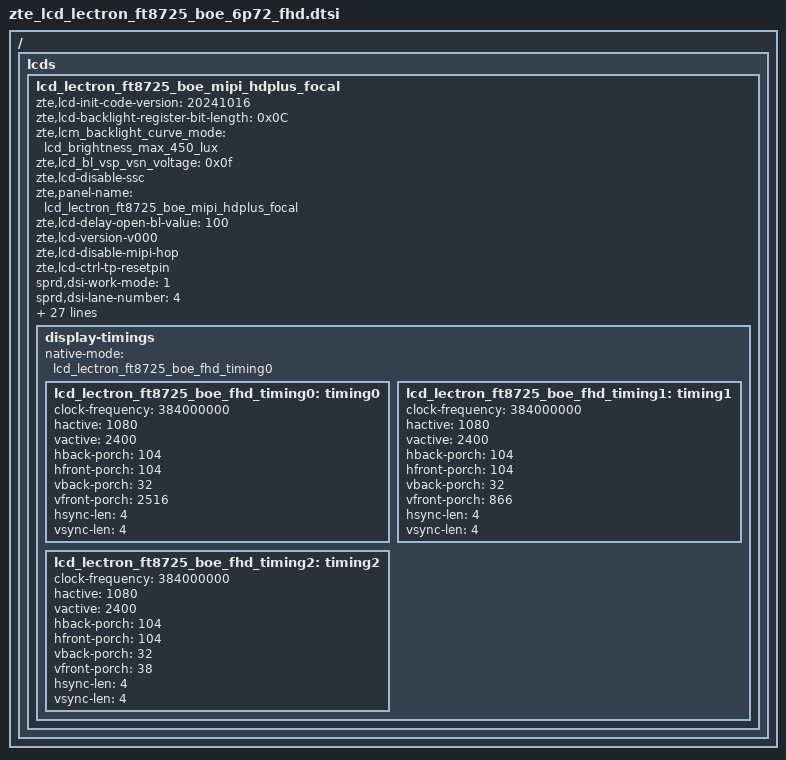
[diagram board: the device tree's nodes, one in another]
/ {
	fragment {
		target-path = "/";
		__overlay__ {
			lcds {
				lcd_lectron_ft8725_boe_mipi_hdplus_focal: lcd_lectron_ft8725_boe_mipi_hdplus_focal {
					zte,lcd-init-code-version = "20241016";

					zte,lcd-backlight-register-bit-length = <0x0C>;
					zte,lcm_backlight_curve_mode = "lcd_brightness_max_450_lux";
					zte,lcd_bl_vsp_vsn_voltage = <0x0f>;
					zte,lcd-disable-ssc;
					zte,panel-name = "lcd_lectron_ft8725_boe_mipi_hdplus_focal";
					zte,lcd-delay-open-bl-value = <100>;
					zte,lcd-version-v000;
					zte,lcd-disable-mipi-hop;
					zte,lcd-ctrl-tp-resetpin;

					sprd,dsi-work-mode = <1>;
					sprd,dsi-lane-number = <4>;
					sprd,dsi-color-format = "dsc";
					sprd,phy-bit-clock = <1100000>;
					sprd,phy-escape-clock = <20000>;/* kHz */

					sprd,width-mm = <7008>;
					sprd,height-mm = <15574>;
					sprd,vrr-enabled;
					sprd,vrr-max-layers = <3>;
					sprd,slice-width = <540>;
					sprd,slice-height = <8>;
					sprd,output-bpc = <8>;
					sprd,dsc-enable = <1>;
					sprd,dual-dsi-enable = <0>;

					sprd,esd-check-enable = <1>;/* 0:close , 1:open */
					sprd,esd-check-mode = <1>;/* 0:REG ,1:TE  */
					sprd,esd-check-period = <2000>;
					sprd,esd-check-register = <0x0A>;
					sprd,esd-check-value = <0x9C>;

					sprd,dphy-taget-val = <5>;

					sprd,reset-on-sequence = <1 5>, <0 15>, <1 25>;
					sprd,reset-off-sequence = <1 20>;

					sprd,use-gen-write;
					sprd,initial-command = [
29 00 00 02 00 00
29 00 00 04 FF 87 25 01
29 00 00 02 00 80
29 00 00 03 FF 87 25
29 00 00 02 00 A3
29 00 00 05 B3 09 60 00 18
29 00 00 02 00 AD
29 00 00 04 C1 FF FF FF
29 00 00 02 00 80
29 00 00 07 C0 00 4A 00 36 00 14
29 00 00 02 00 90
29 00 00 07 C0 00 4A 00 36 00 14
29 00 00 02 00 A0
29 00 00 07 C0 00 6E 00 36 00 14
29 00 00 02 00 B0
29 00 00 06 C0 00 CD 00 36 14
29 00 00 02 00 C1
29 00 00 09 C0 00 94 00 81 00 63 00 C1
29 00 00 02 00 70
29 00 00 07 C0 00 AD 00 36 00 14
29 00 00 02 00 A3
29 00 00 07 C1 00 67 00 40 00 02
29 00 00 02 00 B7
29 00 00 03 C1 00 4E
29 00 00 02 00 7B
29 00 00 03 CE FF FF
29 00 00 02 00 80
29 00 00 11 CE 01 81 FF FF 00 BC 00 C8 00 C8 00 C4 00 8C 00 CC
29 00 00 02 00 90
29 00 00 10 CE 00 B7 0F 7D 00 B7 80 FF FF 00 0B B8 11 1B 0F
29 00 00 02 00 A0
29 00 00 04 CE 00 00 00
29 00 00 02 00 B0
29 00 00 04 CE 22 00 00
29 00 00 02 00 D1
29 00 00 08 CE 00 00 01 00 00 00 00
29 00 00 02 00 E1
29 00 00 0C CE 0A 02 FB 02 FB 02 FB 00 00 00 00
29 00 00 02 00 F1
29 00 00 0A CE 24 1B 12 01 0B 00 E7 01 0A
29 00 00 02 00 B0
29 00 00 05 CF 00 00 B2 B6
29 00 00 02 00 B5
29 00 00 05 CF 05 05 62 66
29 00 00 02 00 C0
29 00 00 05 CF 09 09 5B 5F
29 00 00 02 00 C5
29 00 00 05 CF 09 09 61 65
29 00 00 02 00 60
29 00 00 09 CF 00 00 85 89 05 05 4D 51
29 00 00 02 00 70
29 00 00 09 CF 00 00 C3 C7 05 05 5B 5F
29 00 00 02 00 D1
29 00 00 0D C1 0B 60 0F DC 1B 15 05 AF 07 E5 0D 81
29 00 00 02 00 E1
29 00 00 03 C1 0F DC
29 00 00 02 00 E4
29 00 00 0D CF 09 FA 09 F9 09 F9 09 F9 09 F9 09 F9
29 00 00 02 00 80
29 00 00 03 C1 44 44
29 00 00 02 00 90
29 00 00 02 C1 03
29 00 00 02 00 F5
29 00 00 02 CF 00
29 00 00 02 00 F6
29 00 00 02 CF 78
29 00 00 02 00 F1
29 00 00 02 CF 78
29 00 00 02 00 85
29 00 00 02 B4 77
29 00 00 02 00 91
29 00 00 02 C4 88
29 00 00 02 00 80
29 00 00 03 C5 87 59
29 00 00 02 00 87
29 00 00 03 C5 0A 0A
29 00 00 02 00 93
29 00 00 02 C1 82
29 00 00 02 00 9E
29 00 00 02 C5 87
29 00 00 02 00 88
29 00 00 02 C4 08
29 00 00 02 00 80
29 00 00 0D C2 83 01 01 86 82 01 01 86 8D 02 01 86
29 00 00 02 00 A0
29 00 00 10 C2 8A 07 00 01 87 89 08 00 01 87 88 09 00 01 87
29 00 00 02 00 B0
29 00 00 06 C2 87 0A 00 01 87
29 00 00 02 00 E0
29 00 00 05 C2 33 33 00 00
29 00 00 02 00 E8
29 00 00 09 C2 12 00 0A 0A 03 88 00 00
29 00 00 02 00 D0
29 00 00 11 C3 35 0A 00 00 35 0A 00 00 35 0A 00 00 35 0A 00 00
29 00 00 02 00 E0
29 00 00 11 C3 35 0A 00 00 35 0A 00 00 35 0A 00 00 35 0A 00 00
29 00 00 02 00 80
29 00 00 11 CB CD CD CD 00 CD CC 00 CD CE FE CD 00 CC CC 00 00
29 00 00 02 00 90
29 00 00 11 CB 0C 00 00 00 0C 0C 00 00 0C 00 00 00 00 00 00 00
29 00 00 02 00 A0
29 00 00 09 CB 00 00 00 00 00 00 00 00
29 00 00 02 00 B0
29 00 00 05 CB 50 41 A4 00
29 00 00 02 00 C0
29 00 00 05 CB 50 41 A4 00
29 00 00 02 00 D5
29 00 00 0C CB 83 00 83 83 00 83 83 00 83 83 00
29 00 00 02 00 E0
29 00 00 0E CB 83 83 00 83 83 00 83 83 00 83 83 00 83
29 00 00 02 00 80
29 00 00 11 CC 2C 2C 2C 18 17 16 2C 07 06 09 08 2C 25 26 2C 24
29 00 00 02 00 90
29 00 00 09 CC 2C 22 23 23 04 03 02 26
29 00 00 02 00 80
29 00 00 11 CD 2C 2C 2C 18 17 16 2C 07 06 09 08 2C 25 26 2C 24
29 00 00 02 00 90
29 00 00 09 CD 2C 22 23 23 04 03 02 26
29 00 00 02 00 A0
29 00 00 11 CC 2C 2C 2C 18 17 16 2C 08 09 06 07 2C 25 22 2C 24
29 00 00 02 00 B0
29 00 00 09 CC 2C 26 23 23 04 02 03 26
29 00 00 02 00 A0
29 00 00 11 CD 2C 2C 2C 18 17 16 2C 08 09 06 07 2C 25 22 2C 24
29 00 00 02 00 B0
29 00 00 09 CD 2C 26 23 23 04 02 03 26
29 00 00 02 00 86
29 00 00 09 C0 01 01 01 00 10 10 10 06
29 00 00 02 00 96
29 00 00 09 C0 01 02 01 00 13 13 13 03
29 00 00 02 00 A6
29 00 00 09 C0 01 02 01 00 1D 1D 1D 03
29 00 00 02 00 A3
29 00 00 07 CE 01 01 01 01 10 06
29 00 00 02 00 B3
29 00 00 07 CE 00 01 01 01 10 06
29 00 00 02 00 76
29 00 00 09 C0 01 02 01 02 2E 2E 2E 04
29 00 00 02 00 82
29 00 00 03 A7 20 00
29 00 00 02 00 8D
29 00 00 02 A7 02
29 00 00 02 00 8F
29 00 00 02 A7 01
29 00 00 02 00 93
29 00 00 02 C5 37
29 00 00 02 00 97
29 00 00 02 C5 37
29 00 00 02 00 9A
29 00 00 02 C5 23
29 00 00 02 00 9C
29 00 00 02 C5 23
29 00 00 02 00 B6
29 00 00 05 C5 2D 2D 19 19
29 00 00 02 00 00
29 00 00 03 D8 2F 2F
29 00 00 02 00 88
29 00 00 02 C4 08
29 00 00 02 00 80
29 00 00 02 A7 03
29 00 00 02 00 A0
29 00 00 11 C3 00 01 23 45 21 03 45 00 00 00 21 03 45 01 23 45
29 00 00 02 00 B1
29 00 00 02 F5 1F
29 00 00 02 00 CB
29 00 00 02 C0 11
29 00 00 02 00 88
29 00 00 02 C4 08
29 00 00 02 00 94
29 00 00 02 E9 00
29 00 00 02 00 9A
29 00 00 02 C4 11
29 00 00 02 00 95
29 00 00 02 E9 10
29 00 00 02 00 82
29 00 00 02 F5 00
29 00 00 02 00 93
29 00 00 02 F5 00
29 00 00 02 00 99
29 00 00 02 CF 50
29 00 00 02 00 9C
29 00 00 02 F5 00
29 00 00 02 00 9E
29 00 00 02 F5 00
29 00 00 02 00 B0
29 00 00 07 C5 10 4A 01 1F 4A 00
29 00 00 02 00 A0
29 00 00 08 B0 00 00 00 00 00 1D 01
29 00 00 02 00 93
29 00 00 02 E9 AA
29 00 00 02 00 95
29 00 00 02 E9 B0
29 00 00 02 00 9B
29 00 00 02 C4 08
29 00 00 02 00 80
29 00 00 02 A4 C8
29 00 00 02 00 E8
29 00 00 02 C0 40
29 00 00 02 00 00
29 00 00 29 E1 00 04 08 0F 3F 1B 23 29 34 08 3C 43 49 4E 40 52 5B 62 69 C5 70 77 7E 87 5C 90 96 9C A4 DC AC B7 C5 CE E1 DA EA F6 FF 18
29 00 00 02 00 30
29 00 00 29 E1 00 04 08 0F 3F 1B 23 29 34 08 3C 43 49 4E 40 52 5B 62 69 C5 70 77 7E 87 5C 90 96 9C A4 DC AC B7 C5 CE E1 DA EA F6 FF 18
29 00 00 02 00 60
29 00 00 29 E1 00 04 08 0F 3F 1B 23 29 34 08 3C 43 49 4E 40 52 5B 62 69 C5 70 77 7E 87 5C 90 96 9C A4 DC AC B7 C5 CE E1 DA EA F6 FF 18
29 00 00 02 00 90
29 00 00 29 E1 00 04 08 0F 3F 1B 23 29 34 08 3C 43 49 4E 40 52 5B 62 69 C5 70 77 7E 87 5C 90 96 9C A4 DC AC B7 C5 CE E1 DA EA F6 FF 18
29 00 00 02 00 C0
29 00 00 29 E1 00 04 08 0F 3F 1B 23 29 34 08 3C 43 49 4E 40 52 5B 62 69 C5 70 77 7E 87 5C 90 96 9C A4 DC AC B7 C5 CE E1 DA EA F6 FF 18
29 00 00 02 00 F0
29 00 00 11 E1 00 04 08 0F 3F 1B 23 29 34 08 3C 43 49 4E 40 52
29 00 00 02 00 00
29 00 00 19 E2 5B 62 69 C5 70 77 7E 87 5C 90 96 9C A4 DC AC B7 C5 CE E1 DA EA F6 FF 18
29 00 00 02 00 00
29 00 00 29 E3 00 04 08 0F 3F 1B 23 29 34 08 3C 43 49 4E 40 52 5B 62 69 C5 70 77 7E 87 5C 90 96 9C A4 DC AC B7 C4 CD E1 D9 E9 F3 FF 18
29 00 00 02 00 30
29 00 00 29 E3 00 04 08 0F 3F 1B 23 29 34 08 3C 43 49 4E 40 52 5B 62 69 C5 70 77 7E 87 5C 90 96 9C A4 DC AC B7 C4 CD E1 D9 E9 F3 FF 18
29 00 00 02 00 60
29 00 00 29 E3 00 04 08 0F 3F 1B 23 29 34 08 3C 43 49 4E 40 52 5B 62 69 C5 70 77 7E 87 5C 90 96 9C A4 DC AC B7 C4 CD E1 D9 E9 F3 FF 18
29 00 00 02 00 90
29 00 00 29 E3 00 04 08 0F 3F 1B 23 29 34 08 3C 43 49 4E 40 52 5B 62 69 C5 70 77 7E 87 5C 90 96 9C A4 DC AC B7 C4 CD E1 D9 E9 F3 FF 18
29 00 00 02 00 C0
29 00 00 29 E3 00 04 08 0F 3F 1B 23 29 34 08 3C 43 49 4E 40 52 5B 62 69 C5 70 77 7E 87 5C 90 96 9C A4 DC AC B7 C4 CD E1 D9 E9 F3 FF 18
29 00 00 02 00 F0
29 00 00 11 E3 00 04 08 0F 3F 1B 23 29 34 08 3C 43 49 4E 40 52
29 00 00 02 00 00
29 00 00 19 E4 5B 62 69 C5 70 77 7E 87 5C 90 96 9C A4 DC AC B7 C4 CD E1 D9 E9 F3 FF 18
29 00 00 02 00 80
29 00 00 0D CA EB D6 C5 B8 AE A4 9D 96 91 8C 87 83
29 00 00 02 00 90
29 00 00 0A CA FD FF EA FC FF CC FA FF 66
29 00 00 02 00 E0
29 00 00 02 CF 34
29 00 00 02 00 85
29 00 00 02 A7 00
29 00 00 02 00 80
29 00 00 02 B3 22
29 00 00 02 00 B0
29 00 00 02 B3 00
29 00 00 02 00 82
29 00 00 03 CE 17 17
29 00 00 02 00 90
29 00 00 02 A7 00
29 00 00 02 00 E0
29 00 00 02 CE 00
29 00 00 02 00 FC
29 00 00 03 C0 00 16
29 00 00 02 00 81
/* Started by AICoder, pid:v5def2535cu8b4314e160bf2d0ee0402947977ac */
29 00 00 02 A4 23
29 00 00 02 00 90
29 00 00 02 E9 50
29 00 00 02 00 B0
29 00 00 0F B4 00 08 02 00 00 BB 00 07 0D B7 0C B7 10 F0
29 00 00 02 00 87
29 00 00 02 F5 00
29 00 00 02 00 BE
29 00 00 03 C5 C0 C0
/* Ended by AICoder, pid:v5def2535cu8b4314e160bf2d0ee0402947977ac */
29 00 00 02 00 87
29 00 00 02 C4 08
29 00 00 02 00 81
29 00 00 03 A4 23 23
29 00 00 02 00 00
29 00 00 04 FF FF FF FF
29 00 00 02 35 00
29 00 00 03 51 00 00
29 00 00 02 53 24
05 78 00 01 11
05 14 00 01 29
					];
					sprd,sleep-in-command = [
						39 14 00 03 28 00 00
						39 78 00 03 10 00 00
						];
					sprd,sleep-out-command = [
						39 78 00 03 11 00 00
						39 14 00 03 29 00 00
						];
					display-timings {
						native-mode = <&lcd_lectron_ft8725_boe_fhd_timing0>;
						lcd_lectron_ft8725_boe_fhd_timing0: timing0 {
							clock-frequency = <384000000>;
							hactive = <1080>;
							vactive = <2400>;
							hback-porch = <104>;
							hfront-porch = <104>;
							vback-porch = <32>;
							vfront-porch = <2516>;
							hsync-len = <4>;
							vsync-len = <4>;
						};
						lcd_lectron_ft8725_boe_fhd_timing1: timing1 {
							clock-frequency = <384000000>;
							hactive = <1080>;
							vactive = <2400>;
							hback-porch = <104>;
							hfront-porch = <104>;
							vback-porch = <32>;
							vfront-porch = <866>;
							hsync-len = <4>;
							vsync-len = <4>;
						};
						lcd_lectron_ft8725_boe_fhd_timing2: timing2 {
							clock-frequency = <384000000>;
							hactive = <1080>;
							vactive = <2400>;
							hback-porch = <104>;
							hfront-porch = <104>;
							vback-porch = <32>;
							vfront-porch = <38>;
							hsync-len = <4>;
							vsync-len = <4>;
						};
					};
				};
			};
		};
	};
};
